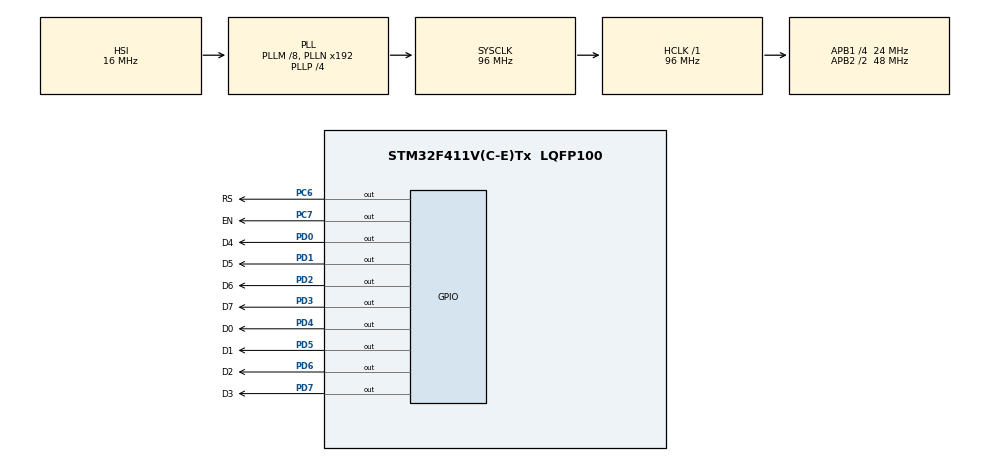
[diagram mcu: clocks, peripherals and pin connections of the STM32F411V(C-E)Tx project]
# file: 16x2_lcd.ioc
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Mcu.Family=STM32F4
Mcu.Name=STM32F411V(C-E)Tx
Mcu.Package=LQFP100
NVIC.PriorityGroup=NVIC_PRIORITYGROUP_0
PC6.GPIO_Label=RS
PC6.Signal=GPIO_Output
PC7.GPIO_Label=EN
PC7.Signal=GPIO_Output
PD0.GPIO_Label=D4
PD0.Signal=GPIO_Output
PD1.GPIO_Label=D5
PD1.Signal=GPIO_Output
PD2.GPIO_Label=D6
PD2.Signal=GPIO_Output
PD3.GPIO_Label=D7
PD3.Signal=GPIO_Output
PD4.GPIO_Label=D0
PD4.Signal=GPIO_Output
PD5.GPIO_Label=D1
PD5.Signal=GPIO_Output
PD6.GPIO_Label=D2
PD6.Signal=GPIO_Output
PD7.GPIO_Label=D3
PD7.Signal=GPIO_Output
ProjectManager.HeapSize=0x200
ProjectManager.StackSize=0x400
ProjectManager.TargetToolchain=SW4STM32
RCC.48MHZClocksFreq_Value=48000000
RCC.AHBFreq_Value=96000000
RCC.APB1CLKDivider=RCC_HCLK_DIV4
RCC.APB1Freq_Value=24000000
RCC.APB1TimFreq_Value=48000000
RCC.APB2CLKDivider=RCC_HCLK_DIV2
RCC.APB2Freq_Value=48000000
RCC.APB2TimFreq_Value=96000000
RCC.CortexFreq_Value=96000000
RCC.HCLKFreq_Value=96000000
RCC.HSE_VALUE=8000000
RCC.HSI_VALUE=16000000
RCC.LSE_VALUE=32768
RCC.PLLI2SM=5
RCC.PLLI2SN=200
RCC.PLLM=8
RCC.PLLP=RCC_PLLP_DIV4
RCC.PLLQ=8
RCC.SYSCLKFreq_VALUE=96000000
RCC.SYSCLKSource=RCC_SYSCLKSOURCE_PLLCLK
RCC.VCOOutputFreq_Value=384000000
board=32F411EDISCOVERY

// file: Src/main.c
/**
  ******************************************************************************
  * @file           : main.c
  * @brief          : Main program body
  ******************************************************************************
  ** This notice applies to any and all portions of this file
  * that are not between comment pairs USER CODE BEGIN and
  * USER CODE END. Other portions of this file, whether
  * inserted by the user or by software development tools
  * are owned by their respective copyright owners.
  *
  * COPYRIGHT(c) 2018 STMicroelectronics
  *
  * Redistribution and use in source and binary forms, with or without modification,
  * are permitted provided that the following conditions are met:
  *   1. Redistributions of source code must retain the above copyright notice,
  *      this list of conditions and the following disclaimer.
  *   2. Redistributions in binary form must reproduce the above copyright notice,
  *      this list of conditions and the following disclaimer in the documentation
  *      and/or other materials provided with the distribution.
  *   3. Neither the name of STMicroelectronics nor the names of its contributors
  *      may be used to endorse or promote products derived from this software
  *      without specific prior written permission.
  *
  * THIS SOFTWARE IS PROVIDED BY THE COPYRIGHT HOLDERS AND CONTRIBUTORS "AS IS"
  * AND ANY EXPRESS OR IMPLIED WARRANTIES, INCLUDING, BUT NOT LIMITED TO, THE
  * IMPLIED WARRANTIES OF MERCHANTABILITY AND FITNESS FOR A PARTICULAR PURPOSE ARE
  * DISCLAIMED. IN NO EVENT SHALL THE COPYRIGHT HOLDER OR CONTRIBUTORS BE LIABLE
  * FOR ANY DIRECT, INDIRECT, INCIDENTAL, SPECIAL, EXEMPLARY, OR CONSEQUENTIAL
  * DAMAGES (INCLUDING, BUT NOT LIMITED TO, PROCUREMENT OF SUBSTITUTE GOODS OR
  * SERVICES; LOSS OF USE, DATA, OR PROFITS; OR BUSINESS INTERRUPTION) HOWEVER
  * CAUSED AND ON ANY THEORY OF LIABILITY, WHETHER IN CONTRACT, STRICT LIABILITY,
  * OR TORT (INCLUDING NEGLIGENCE OR OTHERWISE) ARISING IN ANY WAY OUT OF THE USE
  * OF THIS SOFTWARE, EVEN IF ADVISED OF THE POSSIBILITY OF SUCH DAMAGE.
  *
  ******************************************************************************
  */
#include "main.h"
#include "stm32f4xx_hal.h"

/* USER CODE BEGIN Includes */

#include "lcd.h"

/* USER CODE END Includes */

/* USER CODE BEGIN PV */
/* Private variables ---------------------------------------------------------*/

/* USER CODE END PV */

void SystemClock_Config(void);
static void MX_GPIO_Init(void);

/* USER CODE BEGIN PFP */
/* Private function prototypes -----------------------------------------------*/

/* USER CODE END PFP */

int main(void)
{

  /* MCU Configuration----------------------------------------------------------*/

  /* Reset of all peripherals, Initializes the Flash interface and the Systick. */
  HAL_Init();

  /* Configure the system clock */
  SystemClock_Config();

  /* Initialize all configured peripherals */
  MX_GPIO_Init();
  /* USER CODE BEGIN 2 */

  Lcd_PortType ports[] = {
		  D4_GPIO_Port, D5_GPIO_Port, D6_GPIO_Port, D7_GPIO_Port
  };

  Lcd_PinType pins[] = {D4_Pin, D5_Pin, D6_Pin, D7_Pin};

  Lcd_HandleTypeDef lcd = Lcd_create(ports, pins, RS_GPIO_Port, RS_Pin, EN_GPIO_Port, EN_Pin, LCD_4_BIT_MODE);

  Lcd_string(&lcd, "4ilo");

  Lcd_cursor(&lcd, 1,6);
  Lcd_int(&lcd, -500);

  /* USER CODE END 2 */

  /* Infinite loop */
  while (1)
  {

  }

}

void SystemClock_Config(void)
{

  RCC_OscInitTypeDef RCC_OscInitStruct;
  RCC_ClkInitTypeDef RCC_ClkInitStruct;

    /**Configure the main internal regulator output voltage
    */
  __HAL_RCC_PWR_CLK_ENABLE();

  __HAL_PWR_VOLTAGESCALING_CONFIG(PWR_REGULATOR_VOLTAGE_SCALE1);

    /**Initializes the CPU, AHB and APB busses clocks
    */
  RCC_OscInitStruct.OscillatorType = RCC_OSCILLATORTYPE_HSI;
  RCC_OscInitStruct.HSIState = RCC_HSI_ON;
  RCC_OscInitStruct.HSICalibrationValue = 16;
  RCC_OscInitStruct.PLL.PLLState = RCC_PLL_ON;
  RCC_OscInitStruct.PLL.PLLSource = RCC_PLLSOURCE_HSI;
  RCC_OscInitStruct.PLL.PLLM = 8;
  RCC_OscInitStruct.PLL.PLLN = 192;
  RCC_OscInitStruct.PLL.PLLP = RCC_PLLP_DIV4;
  RCC_OscInitStruct.PLL.PLLQ = 8;
  if (HAL_RCC_OscConfig(&RCC_OscInitStruct) != HAL_OK)
  {
    _Error_Handler(__FILE__, __LINE__);
  }

    /**Initializes the CPU, AHB and APB busses clocks
    */
  RCC_ClkInitStruct.ClockType = RCC_CLOCKTYPE_HCLK|RCC_CLOCKTYPE_SYSCLK
                              |RCC_CLOCKTYPE_PCLK1|RCC_CLOCKTYPE_PCLK2;
  RCC_ClkInitStruct.SYSCLKSource = RCC_SYSCLKSOURCE_PLLCLK;
  RCC_ClkInitStruct.AHBCLKDivider = RCC_SYSCLK_DIV1;
  RCC_ClkInitStruct.APB1CLKDivider = RCC_HCLK_DIV4;
  RCC_ClkInitStruct.APB2CLKDivider = RCC_HCLK_DIV2;

  if (HAL_RCC_ClockConfig(&RCC_ClkInitStruct, FLASH_LATENCY_3) != HAL_OK)
  {
    _Error_Handler(__FILE__, __LINE__);
  }

    /**Configure the Systick interrupt time
    */
  HAL_SYSTICK_Config(HAL_RCC_GetHCLKFreq()/1000);

    /**Configure the Systick
    */
  HAL_SYSTICK_CLKSourceConfig(SYSTICK_CLKSOURCE_HCLK);

  /* SysTick_IRQn interrupt configuration */
  HAL_NVIC_SetPriority(SysTick_IRQn, 0, 0);
}

/** Configure pins as
        * Analog
        * Input
        * Output
        * EVENT_OUT
        * EXTI
*/
static void MX_GPIO_Init(void)
{

  GPIO_InitTypeDef GPIO_InitStruct;

  /* GPIO Ports Clock Enable */
  __HAL_RCC_GPIOC_CLK_ENABLE();
  __HAL_RCC_GPIOD_CLK_ENABLE();

  /*Configure GPIO pin Output Level */
  HAL_GPIO_WritePin(GPIOC, RS_Pin|EN_Pin, GPIO_PIN_RESET);

  /*Configure GPIO pin Output Level */
  HAL_GPIO_WritePin(GPIOD, D4_Pin|D5_Pin|D6_Pin|D7_Pin
                          |D0_Pin|D1_Pin|D2_Pin|D3_Pin, GPIO_PIN_RESET);

  /*Configure GPIO pins : RS_Pin EN_Pin */
  GPIO_InitStruct.Pin = RS_Pin|EN_Pin;
  GPIO_InitStruct.Mode = GPIO_MODE_OUTPUT_PP;
  GPIO_InitStruct.Pull = GPIO_NOPULL;
  GPIO_InitStruct.Speed = GPIO_SPEED_FREQ_LOW;
  HAL_GPIO_Init(GPIOC, &GPIO_InitStruct);

  /*Configure GPIO pins : D4_Pin D5_Pin D6_Pin D7_Pin
                           D0_Pin D1_Pin D2_Pin D3_Pin */
  GPIO_InitStruct.Pin = D4_Pin|D5_Pin|D6_Pin|D7_Pin
                          |D0_Pin|D1_Pin|D2_Pin|D3_Pin;
  GPIO_InitStruct.Mode = GPIO_MODE_OUTPUT_PP;
  GPIO_InitStruct.Pull = GPIO_NOPULL;
  GPIO_InitStruct.Speed = GPIO_SPEED_FREQ_LOW;
  HAL_GPIO_Init(GPIOD, &GPIO_InitStruct);

}

void _Error_Handler(char *file, int line)
{
  while(1)
  {
  }
}

/************************ (C) COPYRIGHT STMicroelectronics *****END OF FILE****/
